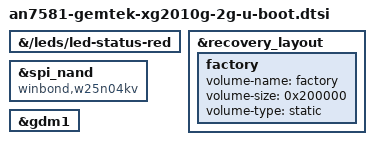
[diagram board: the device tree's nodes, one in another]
// SPDX-License-Identifier: (GPL-2.0-only OR BSD-2-Clause)

#include "an7581-u-boot.dtsi"
#include "an758x-recovery-layout-u-boot.dtsi"

/*
 * The front status LED is a four-colour assembly; point the boot-time
 * "status LED is alive" indicator at the red die, matching the vendor
 * behaviour. The HTTP recovery pattern drives all four.
 */
status_led: &{/leds/led-status-red} {
};

#include "an758x-status-led-u-boot.dtsi"

&recovery_layout {
	factory {
		volume-name = "factory";
		volume-size = <0x200000>;
		volume-type = "static";
		bootph-all;
	};
};

&spi_nand {
	/* Keep the board-specific NAND compatible selected during U-Boot fixups. */
	compatible = "winbond,w25n04kv", "spi-nand";
};

&gdm1 {
	/* Recovery networking requires gdm1 before relocation. */
	status = "okay";
	bootph-all;
};
